# ATtiny15 device description
Architecture: AVR8; Family: tinyAVR
Registers are 8-bit, access not given, no defined reset value unless marked. A register's access mark holds for its fields unless they carry their own. Offsets are from the block's base; [hi:lo] are bit positions.

## EEPROM
Instances: EEPROM 0x00
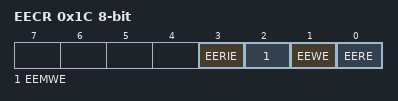
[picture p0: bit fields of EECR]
0x1C EECR — EEPROM Control Register
  [3] EERIE — EEProm Ready Interrupt Enable
  [2] EEMWE — EEPROM Master Write Enable
  [1] EEWE — EEPROM Write Enable
  [0] EERE — EEPROM Read Enable
0x1D EEDR — EEPROM Data Register
0x1E EEAR bits used 5:0 — EEPROM Read/Write Access

## PORTB — I/O Port
Instances: PORTB 0x00
0x16 PINB bits used 5:0 — Input Pins, Port B
0x17 DDRB bits used 5:0 — Data Direction Register, Port B
0x18 PORTB bits used 4:0 — Data Register, Port B

## TC0 (TC8 module) — Timer/Counter, 8-bit
Instances: TC0 0x00
0x32 TCNT0 — Timer Counter 0
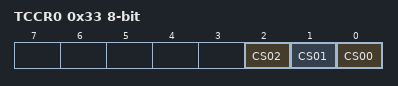
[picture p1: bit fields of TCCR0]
0x33 TCCR0 — Timer/Counter0 Control Register
  [2] CS02 — Clock Select0 bit 2
    0=NO_CLOCK_SOURCE_STOPPED; 1=RUNNING_NO_PRESCALING; 2=RUNNING_CLK_8; 3=RUNNING_CLK_64; 4=RUNNING_CLK_256; 5=RUNNING_CLK_1024; 6=RUNNING_EXTCLK_TN_FALLING_EDGE; 7=RUNNING_EXTCLK_TN_RISING_EDGE
  [1] CS01 — Clock Select0 bit 1
  [0] CS00 — Clock Select0 bit 0
0x38 TIFR — Timer/Counter Interrupt Flag register
  [1] TOV0 — Timer/Counter0 Overflow Flag
0x39 TIMSK — Timer/Counter Interrupt Mask Register
  [1] TOIE0 — Timer/Counter0 Overflow Interrupt Enable

## TC1 (TC8 module) — Timer/Counter, 8-bit
Instances: TC1 0x00
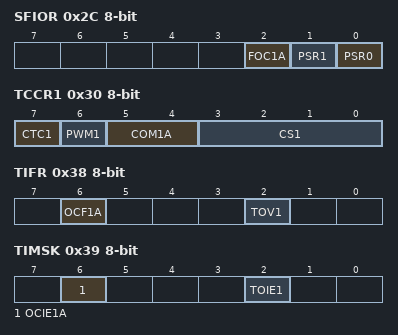
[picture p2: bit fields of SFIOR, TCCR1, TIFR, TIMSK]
0x2C SFIOR — Special Function IO Register
  [2] FOC1A — Force Output Compare 1A
  [1] PSR1 — Prescaler Reset Timer/Counter1
  [0] PSR0 — Prescaler Reset Timer/Counter0
0x2D OCR1B — Output Compare Register
0x2E OCR1A — Output Compare Register
0x2F TCNT1 — Timer/Counter Register
0x30 TCCR1 — Timer/Counter Control Register
  [7] CTC1 — Clear Timer/Counter on Compare Match
  [6] PWM1 — Pulse Width Modulator Enable
  [5:4] COM1A — Compare Output Mode, Bits
    0=DISCONNECTED_FROM_OCN_PWMN; 1=TOGGLE_OCN_PWMN_OUTPUT_LINE; 2=CLEAR_OCN_PWMN_OUTPUT_LINE; 3=SET_OCN_PWMN_OUTPUT_LINE
  [3:0] CS1 — Clock Select Bits
    0=NO_CLOCK_SOURCE_STOPPED; 1=RUNNING_CLK_16; 2=RUNNING_CLK_8; 3=RUNNING_CLK_4; 4=RUNNING_CLK_2; 5=RUNNING_NO_PRESCALING; 6=RUNNING_CLK_2; 7=RUNNING_CLK_4; 8=RUNNING_CLK_8; 9=RUNNING_CLK_16; 10=RUNNING_CLK_32; 11=RUNNING_CLK_64; 12=RUNNING_CLK_128; 13=RUNNING_CLK_256; 14=RUNNING_CLK_512; 15=RUNNING_CLK_1024
0x38 TIFR — Timer/Counter Interrupt Flag Register
  [6] OCF1A — Timer/Counter1 Output Compare Flag 1A
  [2] TOV1 — Timer/Counter1 Overflow Flag
0x39 TIMSK — Timer/Counter Interrupt Mask Register
  [6] OCIE1A — OCIE1A: Timer/Counter1 Output Compare Interrupt Enable
  [2] TOIE1 — Timer/Counter1 Overflow Interrupt Enable

## WDT — Watchdog Timer
Instances: WDT 0x00
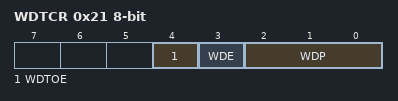
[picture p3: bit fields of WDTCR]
0x21 WDTCR — Watchdog Timer Control Register
  [4] WDTOE — RW
  [3] WDE — Watch Dog Enable
  [2:0] WDP — Watch Dog Timer Prescaler bits
    0=OSCILLATOR_CYCLES_16K; 1=OSCILLATOR_CYCLES_32K; 2=OSCILLATOR_CYCLES_64K; 3=OSCILLATOR_CYCLES_128K; 4=OSCILLATOR_CYCLES_256K; 5=OSCILLATOR_CYCLES_512K; 6=OSCILLATOR_CYCLES_1024K; 7=OSCILLATOR_CYCLES_2048K

## CPU — CPU Registers
Instances: CPU 0x00
0x31 OSCCAL — Status Register
  [7:0] OSCCAL — Oscillator Calibration
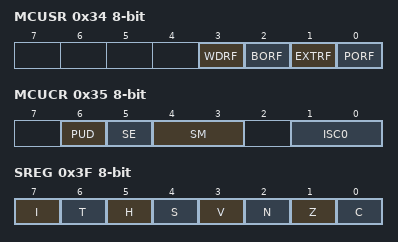
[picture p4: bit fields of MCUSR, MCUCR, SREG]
0x34 MCUSR — MCU Status register
  [3] WDRF — Watchdog Reset Flag
  [2] BORF — Brown-out Reset Flag
  [1] EXTRF — External Reset Flag
  [0] PORF — Power-On Reset Flag
0x35 MCUCR — MCU Control Register
  [6] PUD — Pull-up Disable
  [5] SE — Sleep Enable
  [4:3] SM — Sleep Mode Select Bits
    0=IDLE; 1=ADC (ADC Noise Reduction (If Available)); 2=PDOWN (Power Down)
  [1:0] ISC0 — Interrupt Sense Control 0 bits
    0=LOW_LEVEL_OF_INTX; 1=ANY_LOGICAL_CHANGE_IN_INTX; 2=FALLING_EDGE_OF_INTX; 3=RISING_EDGE_OF_INTX
0x3F SREG — Status Register
  [7] I — Global Interrupt Enable
  [6] T — Bit Copy Storage
  [5] H — Half Carry Flag
  [4] S — Sign Bit
  [3] V — Two's Complement Overflow Flag
  [2] N — Negative Flag
  [1] Z — Zero Flag
  [0] C — Carry Flag
Value list OSCCAL_VALUE_ADDRESSES: 0=1_6_MHz

## EXINT — External Interrupts
Instances: EXINT 0x00
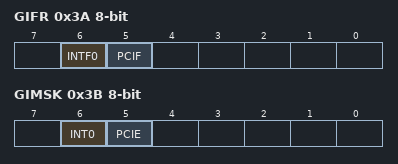
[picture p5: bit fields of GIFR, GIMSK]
0x3A GIFR — General Interrupt Flag register
  [6] INTF0 — External Interrupt Flag 0
  [5] PCIF — Pin Change Interrupt Flag
0x3B GIMSK — General Interrupt Mask Register
  [6] INT0 — External Interrupt Request 0 Enable
  [5] PCIE — Pin Change Interrupt Enable
